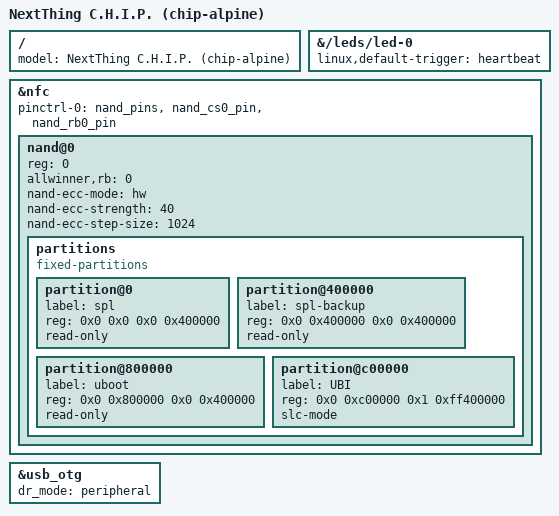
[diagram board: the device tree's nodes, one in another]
#include "sun5i-r8-chip.dts"

/ {
	model = "NextThing C.H.I.P. (chip-alpine)";
};

&{/leds/led-0} {
	linux,default-trigger = "heartbeat";
};

&nfc {
	pinctrl-names = "default";
	pinctrl-0 = <&nand_pins &nand_cs0_pin &nand_rb0_pin>;
	status = "okay";

	nand@0 {
		reg = <0>;
		allwinner,rb = <0>;
		nand-ecc-mode = "hw";
		nand-ecc-strength = <40>;
		nand-ecc-step-size = <1024>;

		partitions {
			compatible = "fixed-partitions";
			#address-cells = <2>;
			#size-cells = <2>;

			partition@0 {
				label = "spl";
				reg = <0x0 0x0 0x0 0x400000>;
				read-only;
			};

			partition@400000 {
				label = "spl-backup";
				reg = <0x0 0x400000 0x0 0x400000>;
				read-only;
			};

			partition@800000 {
				label = "uboot";
				reg = <0x0 0x800000 0x0 0x400000>;
				read-only;
			};

			partition@c00000 {
				label = "UBI";
				reg = <0x0 0xc00000 0x1 0xff400000>;
				slc-mode;
			};
		};
	};
};

&usb_otg {
	dr_mode = "peripheral";
};
